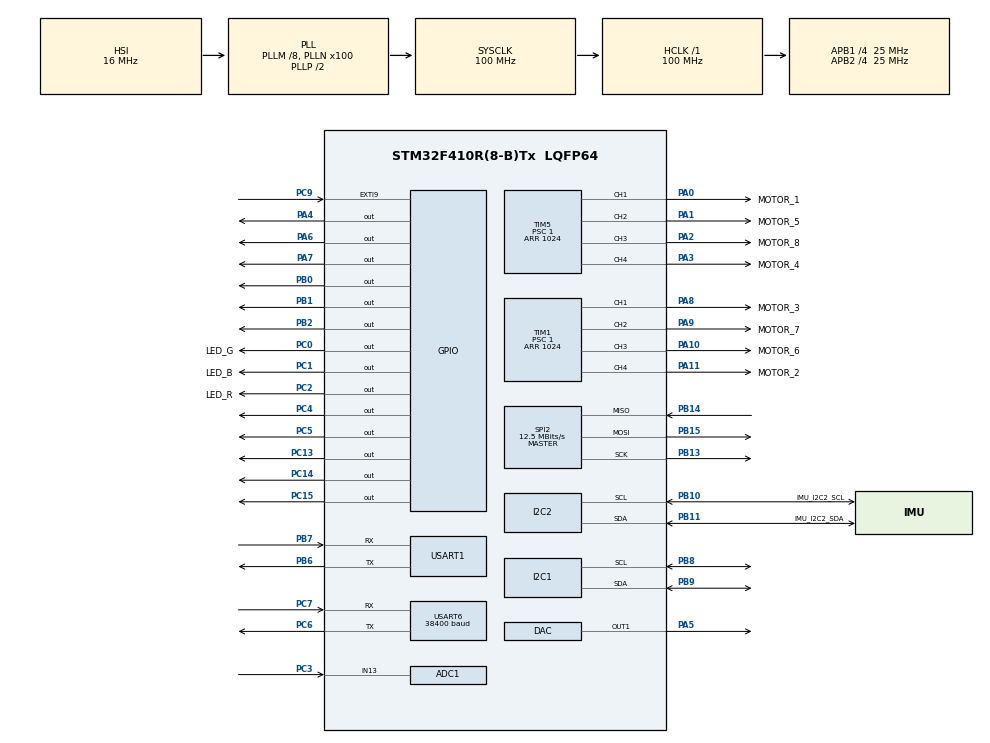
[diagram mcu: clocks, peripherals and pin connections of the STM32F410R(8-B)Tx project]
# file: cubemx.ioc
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ADC1.Channel-0\#ChannelRegularConversion=ADC_CHANNEL_13
ADC1.NbrOfConversionFlag=1
ADC1.Rank-0\#ChannelRegularConversion=1
ADC1.SamplingTime-0\#ChannelRegularConversion=ADC_SAMPLETIME_3CYCLES
ADC1.master=1
Mcu.Family=STM32F4
Mcu.Name=STM32F410R(8-B)Tx
Mcu.Package=LQFP64
NVIC.PriorityGroup=NVIC_PRIORITYGROUP_4
PA0-WKUP.GPIO_Label=MOTOR_1
PA0-WKUP.Signal=S_TIM5_CH1
PA1.GPIO_Label=MOTOR_5
PA1.Signal=S_TIM5_CH2
PA10.GPIO_Label=MOTOR_6
PA10.Signal=S_TIM1_CH3
PA11.GPIO_Label=MOTOR_2
PA11.Signal=S_TIM1_CH4
PA13.Mode=Trace_Asynchronous_SW
PA13.Signal=SYS_JTMS-SWDIO
PA14.Mode=Trace_Asynchronous_SW
PA14.Signal=SYS_JTCK-SWCLK
PA2.GPIO_Label=MOTOR_8
PA2.Signal=S_TIM5_CH3
PA3.GPIO_Label=MOTOR_4
PA3.Signal=S_TIM5_CH4
PA4.Signal=GPIO_Output
PA5.Signal=COMP_DAC1_group
PA6.Signal=GPIO_Output
PA7.Signal=GPIO_Output
PA8.GPIO_Label=MOTOR_3
PA8.Signal=S_TIM1_CH1
PA9.GPIO_Label=MOTOR_7
PA9.Signal=S_TIM1_CH2
PB0.Signal=GPIO_Output
PB1.Signal=GPIO_Output
PB10.GPIO_Label=IMU_I2C2_SCL
PB10.Mode=I2C
PB10.Signal=I2C2_SCL
PB11.GPIO_Label=IMU_I2C2_SDA
PB11.Mode=I2C
PB11.Signal=I2C2_SDA
PB13.Mode=Full_Duplex_Master
PB13.Signal=SPI2_SCK
PB14.Mode=Full_Duplex_Master
PB14.Signal=SPI2_MISO
PB15.Mode=Full_Duplex_Master
PB15.Signal=SPI2_MOSI
PB2.Signal=GPIO_Output
PB3.Mode=Trace_Asynchronous_SW
PB3.Signal=SYS_JTDO-SWO
PB6.Mode=Asynchronous
PB6.Signal=USART1_TX
PB7.Mode=Asynchronous
PB7.Signal=USART1_RX
PB8.Mode=I2C
PB8.Signal=I2C1_SCL
PB9.Mode=I2C
PB9.Signal=I2C1_SDA
PC0.GPIO_Label=LED_G
PC0.Signal=GPIO_Output
PC1.GPIO_Label=LED_B
PC1.Signal=GPIO_Output
PC13-ANTI_TAMP.Signal=GPIO_Output
PC14-OSC32_IN.Signal=GPIO_Output
PC15-OSC32_OUT.Signal=GPIO_Output
PC2.GPIO_Label=LED_R
PC2.Signal=GPIO_Output
PC3.Signal=ADCx_IN13
PC4.Signal=GPIO_Output
PC5.Signal=GPIO_Output
PC6.Mode=Asynchronous
PC6.Signal=USART6_TX
PC7.Mode=Asynchronous
PC7.Signal=USART6_RX
PC9.Signal=GPXTI9
ProjectManager.HeapSize=0x400
ProjectManager.StackSize=0x200
ProjectManager.TargetToolchain=TrueSTUDIO
RCC.48MHZClocksFreq_Value=50000000
RCC.AHBFreq_Value=100000000
RCC.APB1CLKDivider=RCC_HCLK_DIV4
RCC.APB1Freq_Value=25000000
RCC.APB1TimFreq_Value=50000000
RCC.APB2CLKDivider=RCC_HCLK_DIV4
RCC.APB2Freq_Value=25000000
RCC.APB2TimFreq_Value=50000000
RCC.CortexFreq_Value=100000000
RCC.HCLKFreq_Value=100000000
RCC.HSE_VALUE=25000000
RCC.HSI_VALUE=16000000
RCC.LSE_VALUE=32768
RCC.PLLM=8
RCC.PLLN=100
RCC.SYSCLKFreq_VALUE=100000000
RCC.SYSCLKSource=RCC_SYSCLKSOURCE_PLLCLK
RCC.VCOOutputFreq_Value=200000000
SH.ADCx_IN13.0=ADC1_IN13,IN13
SH.COMP_DAC1_group.0=DAC_OUT1,DAC_OUT1
SH.S_TIM1_CH1.0=TIM1_CH1,PWM Generation1 CH1
SH.S_TIM1_CH2.0=TIM1_CH2,PWM Generation2 CH2
SH.S_TIM1_CH3.0=TIM1_CH3,PWM Generation3 CH3
SH.S_TIM1_CH4.0=TIM1_CH4,PWM Generation4 CH4
SH.S_TIM5_CH1.0=TIM5_CH1,PWM Generation1 CH1
SH.S_TIM5_CH2.0=TIM5_CH2,PWM Generation2 CH2
SH.S_TIM5_CH3.0=TIM5_CH3,PWM Generation3 CH3
SH.S_TIM5_CH4.0=TIM5_CH4,PWM Generation4 CH4
SPI2.CalculateBaudRate=12.5 MBits/s
SPI2.Mode=SPI_MODE_MASTER
TIM1.Channel-PWM\ Generation2\ CH2=TIM_CHANNEL_2
TIM1.Channel-PWM\ Generation3\ CH3=TIM_CHANNEL_3
TIM1.Channel-PWM\ Generation4\ CH4=TIM_CHANNEL_4
TIM1.ClockDivision=TIM_CLOCKDIVISION_DIV4
TIM1.Period=1024
TIM1.Prescaler=1
TIM5.Channel-PWM\ Generation2\ CH2=TIM_CHANNEL_2
TIM5.Channel-PWM\ Generation3\ CH3=TIM_CHANNEL_3
TIM5.Channel-PWM\ Generation4\ CH4=TIM_CHANNEL_4
TIM5.Period=1024
TIM5.Prescaler=1
USART6.BaudRate=38400
VP_IWDG_VS_IWDG.Mode=IWDG_Activate
VP_TIM1_VS_ClockSourceINT.Mode=Internal
VP_TIM5_VS_ClockSourceINT.Mode=Internal
board=cubemx

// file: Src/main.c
/**
  ******************************************************************************
  * File Name          : main.c
  * Description        : Main program body
  ******************************************************************************
  *
  * COPYRIGHT(c) 2016 STMicroelectronics
  *
  * Redistribution and use in source and binary forms, with or without modification,
  * are permitted provided that the following conditions are met:
  *   1. Redistributions of source code must retain the above copyright notice,
  *      this list of conditions and the following disclaimer.
  *   2. Redistributions in binary form must reproduce the above copyright notice,
  *      this list of conditions and the following disclaimer in the documentation
  *      and/or other materials provided with the distribution.
  *   3. Neither the name of STMicroelectronics nor the names of its contributors
  *      may be used to endorse or promote products derived from this software
  *      without specific prior written permission.
  *
  * THIS SOFTWARE IS PROVIDED BY THE COPYRIGHT HOLDERS AND CONTRIBUTORS "AS IS"
  * AND ANY EXPRESS OR IMPLIED WARRANTIES, INCLUDING, BUT NOT LIMITED TO, THE
  * IMPLIED WARRANTIES OF MERCHANTABILITY AND FITNESS FOR A PARTICULAR PURPOSE ARE
  * DISCLAIMED. IN NO EVENT SHALL THE COPYRIGHT HOLDER OR CONTRIBUTORS BE LIABLE
  * FOR ANY DIRECT, INDIRECT, INCIDENTAL, SPECIAL, EXEMPLARY, OR CONSEQUENTIAL
  * DAMAGES (INCLUDING, BUT NOT LIMITED TO, PROCUREMENT OF SUBSTITUTE GOODS OR
  * SERVICES; LOSS OF USE, DATA, OR PROFITS; OR BUSINESS INTERRUPTION) HOWEVER
  * CAUSED AND ON ANY THEORY OF LIABILITY, WHETHER IN CONTRACT, STRICT LIABILITY,
  * OR TORT (INCLUDING NEGLIGENCE OR OTHERWISE) ARISING IN ANY WAY OUT OF THE USE
  * OF THIS SOFTWARE, EVEN IF ADVISED OF THE POSSIBILITY OF SUCH DAMAGE.
  *
  ******************************************************************************
  */
#include "main.h"
#include "stm32f4xx_hal.h"

ADC_HandleTypeDef hadc1;

DAC_HandleTypeDef hdac;

I2C_HandleTypeDef hi2c1;
I2C_HandleTypeDef hi2c2;

IWDG_HandleTypeDef hiwdg;

SPI_HandleTypeDef hspi2;

TIM_HandleTypeDef htim1;
TIM_HandleTypeDef htim5;

UART_HandleTypeDef huart1;
UART_HandleTypeDef huart6;

/* USER CODE BEGIN PV */
/* Private variables ---------------------------------------------------------*/

/* USER CODE END PV */

void SystemClock_Config(void);
void Error_Handler(void);
static void MX_GPIO_Init(void);
static void MX_ADC1_Init(void);
static void MX_I2C2_Init(void);
static void MX_TIM1_Init(void);
static void MX_TIM5_Init(void);
static void MX_USART6_UART_Init(void);
static void MX_IWDG_Init(void);
static void MX_I2C1_Init(void);
static void MX_USART1_UART_Init(void);
static void MX_SPI2_Init(void);
static void MX_DAC_Init(void);

void HAL_TIM_MspPostInit(TIM_HandleTypeDef *htim);

/* USER CODE BEGIN PFP */
/* Private function prototypes -----------------------------------------------*/
void dc_main();
/* USER CODE END PFP */

int main(void)
{

  /* MCU Configuration----------------------------------------------------------*/

  /* Reset of all peripherals, Initializes the Flash interface and the Systick. */
  HAL_Init();

  /* Configure the system clock */
  SystemClock_Config();

  /* Initialize all configured peripherals */
  MX_GPIO_Init();
  MX_ADC1_Init();
  MX_I2C2_Init();
  MX_TIM1_Init();
  MX_TIM5_Init();
  MX_USART6_UART_Init();
  MX_IWDG_Init();
  MX_I2C1_Init();
  MX_USART1_UART_Init();
  MX_SPI2_Init();
  MX_DAC_Init();

  /* USER CODE BEGIN 2 */
  dc_main();
  /* USER CODE END 2 */

  /* Infinite loop */
  while (1)
  {

  }

}

/** System Clock Configuration
*/
void SystemClock_Config(void)
{

  RCC_OscInitTypeDef RCC_OscInitStruct;
  RCC_ClkInitTypeDef RCC_ClkInitStruct;

    /**Configure the main internal regulator output voltage
    */
  __HAL_RCC_PWR_CLK_ENABLE();

  __HAL_PWR_VOLTAGESCALING_CONFIG(PWR_REGULATOR_VOLTAGE_SCALE1);

    /**Initializes the CPU, AHB and APB busses clocks
    */
  RCC_OscInitStruct.OscillatorType = RCC_OSCILLATORTYPE_HSI|RCC_OSCILLATORTYPE_LSI;
  RCC_OscInitStruct.HSIState = RCC_HSI_ON;
  RCC_OscInitStruct.HSICalibrationValue = 16;
  RCC_OscInitStruct.LSIState = RCC_LSI_ON;
  RCC_OscInitStruct.PLL.PLLState = RCC_PLL_ON;
  RCC_OscInitStruct.PLL.PLLSource = RCC_PLLSOURCE_HSI;
  RCC_OscInitStruct.PLL.PLLM = 8;
  RCC_OscInitStruct.PLL.PLLN = 100;
  RCC_OscInitStruct.PLL.PLLP = RCC_PLLP_DIV2;
  RCC_OscInitStruct.PLL.PLLQ = 4;
  RCC_OscInitStruct.PLL.PLLR = 2;
  if (HAL_RCC_OscConfig(&RCC_OscInitStruct) != HAL_OK)
  {
    Error_Handler();
  }

    /**Initializes the CPU, AHB and APB busses clocks
    */
  RCC_ClkInitStruct.ClockType = RCC_CLOCKTYPE_HCLK|RCC_CLOCKTYPE_SYSCLK
                              |RCC_CLOCKTYPE_PCLK1|RCC_CLOCKTYPE_PCLK2;
  RCC_ClkInitStruct.SYSCLKSource = RCC_SYSCLKSOURCE_PLLCLK;
  RCC_ClkInitStruct.AHBCLKDivider = RCC_SYSCLK_DIV1;
  RCC_ClkInitStruct.APB1CLKDivider = RCC_HCLK_DIV4;
  RCC_ClkInitStruct.APB2CLKDivider = RCC_HCLK_DIV4;

  if (HAL_RCC_ClockConfig(&RCC_ClkInitStruct, FLASH_LATENCY_3) != HAL_OK)
  {
    Error_Handler();
  }

    /**Configure the Systick interrupt time
    */
  HAL_SYSTICK_Config(HAL_RCC_GetHCLKFreq()/1000);

    /**Configure the Systick
    */
  HAL_SYSTICK_CLKSourceConfig(SYSTICK_CLKSOURCE_HCLK);

  /* SysTick_IRQn interrupt configuration */
  HAL_NVIC_SetPriority(SysTick_IRQn, 0, 0);
}

/* ADC1 init function */
static void MX_ADC1_Init(void)
{

  ADC_ChannelConfTypeDef sConfig;

    /**Configure the global features of the ADC (Clock, Resolution, Data Alignment and number of conversion)
    */
  hadc1.Instance = ADC1;
  hadc1.Init.ClockPrescaler = ADC_CLOCK_SYNC_PCLK_DIV2;
  hadc1.Init.Resolution = ADC_RESOLUTION_12B;
  hadc1.Init.ScanConvMode = DISABLE;
  hadc1.Init.ContinuousConvMode = DISABLE;
  hadc1.Init.DiscontinuousConvMode = DISABLE;
  hadc1.Init.ExternalTrigConvEdge = ADC_EXTERNALTRIGCONVEDGE_NONE;
  hadc1.Init.DataAlign = ADC_DATAALIGN_RIGHT;
  hadc1.Init.NbrOfConversion = 1;
  hadc1.Init.DMAContinuousRequests = DISABLE;
  hadc1.Init.EOCSelection = ADC_EOC_SINGLE_CONV;
  if (HAL_ADC_Init(&hadc1) != HAL_OK)
  {
    Error_Handler();
  }

    /**Configure for the selected ADC regular channel its corresponding rank in the sequencer and its sample time.
    */
  sConfig.Channel = ADC_CHANNEL_13;
  sConfig.Rank = 1;
  sConfig.SamplingTime = ADC_SAMPLETIME_3CYCLES;
  if (HAL_ADC_ConfigChannel(&hadc1, &sConfig) != HAL_OK)
  {
    Error_Handler();
  }

}

/* DAC init function */
static void MX_DAC_Init(void)
{

  DAC_ChannelConfTypeDef sConfig;

    /**DAC Initialization
    */
  hdac.Instance = DAC;
  if (HAL_DAC_Init(&hdac) != HAL_OK)
  {
    Error_Handler();
  }

    /**DAC channel OUT1 config
    */
  sConfig.DAC_Trigger = DAC_TRIGGER_NONE;
  sConfig.DAC_OutputBuffer = DAC_OUTPUTBUFFER_ENABLE;
  if (HAL_DAC_ConfigChannel(&hdac, &sConfig, DAC_CHANNEL_1) != HAL_OK)
  {
    Error_Handler();
  }

}

/* I2C1 init function */
static void MX_I2C1_Init(void)
{

  hi2c1.Instance = I2C1;
  hi2c1.Init.ClockSpeed = 100000;
  hi2c1.Init.DutyCycle = I2C_DUTYCYCLE_2;
  hi2c1.Init.OwnAddress1 = 0;
  hi2c1.Init.AddressingMode = I2C_ADDRESSINGMODE_7BIT;
  hi2c1.Init.DualAddressMode = I2C_DUALADDRESS_DISABLE;
  hi2c1.Init.OwnAddress2 = 0;
  hi2c1.Init.GeneralCallMode = I2C_GENERALCALL_DISABLE;
  hi2c1.Init.NoStretchMode = I2C_NOSTRETCH_DISABLE;
  if (HAL_I2C_Init(&hi2c1) != HAL_OK)
  {
    Error_Handler();
  }

}

/* I2C2 init function */
static void MX_I2C2_Init(void)
{

  hi2c2.Instance = I2C2;
  hi2c2.Init.ClockSpeed = 100000;
  hi2c2.Init.DutyCycle = I2C_DUTYCYCLE_2;
  hi2c2.Init.OwnAddress1 = 0;
  hi2c2.Init.AddressingMode = I2C_ADDRESSINGMODE_7BIT;
  hi2c2.Init.DualAddressMode = I2C_DUALADDRESS_DISABLE;
  hi2c2.Init.OwnAddress2 = 0;
  hi2c2.Init.GeneralCallMode = I2C_GENERALCALL_DISABLE;
  hi2c2.Init.NoStretchMode = I2C_NOSTRETCH_DISABLE;
  if (HAL_I2C_Init(&hi2c2) != HAL_OK)
  {
    Error_Handler();
  }

}

/* IWDG init function */
static void MX_IWDG_Init(void)
{

  hiwdg.Instance = IWDG;
  hiwdg.Init.Prescaler = IWDG_PRESCALER_4;
  hiwdg.Init.Reload = 4095;
  if (HAL_IWDG_Init(&hiwdg) != HAL_OK)
  {
    Error_Handler();
  }

}

/* SPI2 init function */
static void MX_SPI2_Init(void)
{

  hspi2.Instance = SPI2;
  hspi2.Init.Mode = SPI_MODE_MASTER;
  hspi2.Init.Direction = SPI_DIRECTION_2LINES;
  hspi2.Init.DataSize = SPI_DATASIZE_8BIT;
  hspi2.Init.CLKPolarity = SPI_POLARITY_LOW;
  hspi2.Init.CLKPhase = SPI_PHASE_1EDGE;
  hspi2.Init.NSS = SPI_NSS_SOFT;
  hspi2.Init.BaudRatePrescaler = SPI_BAUDRATEPRESCALER_2;
  hspi2.Init.FirstBit = SPI_FIRSTBIT_MSB;
  hspi2.Init.TIMode = SPI_TIMODE_DISABLE;
  hspi2.Init.CRCCalculation = SPI_CRCCALCULATION_DISABLE;
  hspi2.Init.CRCPolynomial = 15;
  if (HAL_SPI_Init(&hspi2) != HAL_OK)
  {
    Error_Handler();
  }

}

/* TIM1 init function */
static void MX_TIM1_Init(void)
{

  TIM_ClockConfigTypeDef sClockSourceConfig;
  TIM_MasterConfigTypeDef sMasterConfig;
  TIM_OC_InitTypeDef sConfigOC;
  TIM_BreakDeadTimeConfigTypeDef sBreakDeadTimeConfig;

  htim1.Instance = TIM1;
  htim1.Init.Prescaler = 1;
  htim1.Init.CounterMode = TIM_COUNTERMODE_UP;
  htim1.Init.Period = 1024;
  htim1.Init.ClockDivision = TIM_CLOCKDIVISION_DIV4;
  htim1.Init.RepetitionCounter = 0;
  if (HAL_TIM_Base_Init(&htim1) != HAL_OK)
  {
    Error_Handler();
  }

  sClockSourceConfig.ClockSource = TIM_CLOCKSOURCE_INTERNAL;
  if (HAL_TIM_ConfigClockSource(&htim1, &sClockSourceConfig) != HAL_OK)
  {
    Error_Handler();
  }

  if (HAL_TIM_PWM_Init(&htim1) != HAL_OK)
  {
    Error_Handler();
  }

  sMasterConfig.MasterOutputTrigger = TIM_TRGO_RESET;
  sMasterConfig.MasterSlaveMode = TIM_MASTERSLAVEMODE_DISABLE;
  if (HAL_TIMEx_MasterConfigSynchronization(&htim1, &sMasterConfig) != HAL_OK)
  {
    Error_Handler();
  }

  sConfigOC.OCMode = TIM_OCMODE_PWM1;
  sConfigOC.Pulse = 0;
  sConfigOC.OCPolarity = TIM_OCPOLARITY_HIGH;
  sConfigOC.OCNPolarity = TIM_OCNPOLARITY_HIGH;
  sConfigOC.OCFastMode = TIM_OCFAST_DISABLE;
  sConfigOC.OCIdleState = TIM_OCIDLESTATE_RESET;
  sConfigOC.OCNIdleState = TIM_OCNIDLESTATE_RESET;
  if (HAL_TIM_PWM_ConfigChannel(&htim1, &sConfigOC, TIM_CHANNEL_1) != HAL_OK)
  {
    Error_Handler();
  }

  if (HAL_TIM_PWM_ConfigChannel(&htim1, &sConfigOC, TIM_CHANNEL_2) != HAL_OK)
  {
    Error_Handler();
  }

  if (HAL_TIM_PWM_ConfigChannel(&htim1, &sConfigOC, TIM_CHANNEL_3) != HAL_OK)
  {
    Error_Handler();
  }

  if (HAL_TIM_PWM_ConfigChannel(&htim1, &sConfigOC, TIM_CHANNEL_4) != HAL_OK)
  {
    Error_Handler();
  }

  sBreakDeadTimeConfig.OffStateRunMode = TIM_OSSR_DISABLE;
  sBreakDeadTimeConfig.OffStateIDLEMode = TIM_OSSI_DISABLE;
  sBreakDeadTimeConfig.LockLevel = TIM_LOCKLEVEL_OFF;
  sBreakDeadTimeConfig.DeadTime = 0;
  sBreakDeadTimeConfig.BreakState = TIM_BREAK_DISABLE;
  sBreakDeadTimeConfig.BreakPolarity = TIM_BREAKPOLARITY_HIGH;
  sBreakDeadTimeConfig.AutomaticOutput = TIM_AUTOMATICOUTPUT_DISABLE;
  if (HAL_TIMEx_ConfigBreakDeadTime(&htim1, &sBreakDeadTimeConfig) != HAL_OK)
  {
    Error_Handler();
  }

  HAL_TIM_MspPostInit(&htim1);

}

/* TIM5 init function */
static void MX_TIM5_Init(void)
{

  TIM_ClockConfigTypeDef sClockSourceConfig;
  TIM_MasterConfigTypeDef sMasterConfig;
  TIM_OC_InitTypeDef sConfigOC;

  htim5.Instance = TIM5;
  htim5.Init.Prescaler = 1;
  htim5.Init.CounterMode = TIM_COUNTERMODE_UP;
  htim5.Init.Period = 1024;
  htim5.Init.ClockDivision = TIM_CLOCKDIVISION_DIV1;
  if (HAL_TIM_Base_Init(&htim5) != HAL_OK)
  {
    Error_Handler();
  }

  sClockSourceConfig.ClockSource = TIM_CLOCKSOURCE_INTERNAL;
  if (HAL_TIM_ConfigClockSource(&htim5, &sClockSourceConfig) != HAL_OK)
  {
    Error_Handler();
  }

  if (HAL_TIM_PWM_Init(&htim5) != HAL_OK)
  {
    Error_Handler();
  }

  sMasterConfig.MasterOutputTrigger = TIM_TRGO_RESET;
  sMasterConfig.MasterSlaveMode = TIM_MASTERSLAVEMODE_DISABLE;
  if (HAL_TIMEx_MasterConfigSynchronization(&htim5, &sMasterConfig) != HAL_OK)
  {
    Error_Handler();
  }

  sConfigOC.OCMode = TIM_OCMODE_PWM1;
  sConfigOC.Pulse = 0;
  sConfigOC.OCPolarity = TIM_OCPOLARITY_HIGH;
  sConfigOC.OCFastMode = TIM_OCFAST_DISABLE;
  if (HAL_TIM_PWM_ConfigChannel(&htim5, &sConfigOC, TIM_CHANNEL_1) != HAL_OK)
  {
    Error_Handler();
  }

  if (HAL_TIM_PWM_ConfigChannel(&htim5, &sConfigOC, TIM_CHANNEL_2) != HAL_OK)
  {
    Error_Handler();
  }

  if (HAL_TIM_PWM_ConfigChannel(&htim5, &sConfigOC, TIM_CHANNEL_3) != HAL_OK)
  {
    Error_Handler();
  }

  if (HAL_TIM_PWM_ConfigChannel(&htim5, &sConfigOC, TIM_CHANNEL_4) != HAL_OK)
  {
    Error_Handler();
  }

  HAL_TIM_MspPostInit(&htim5);

}

/* USART1 init function */
static void MX_USART1_UART_Init(void)
{

  huart1.Instance = USART1;
  huart1.Init.BaudRate = 115200;
  huart1.Init.WordLength = UART_WORDLENGTH_8B;
  huart1.Init.StopBits = UART_STOPBITS_1;
  huart1.Init.Parity = UART_PARITY_NONE;
  huart1.Init.Mode = UART_MODE_TX_RX;
  huart1.Init.HwFlowCtl = UART_HWCONTROL_NONE;
  huart1.Init.OverSampling = UART_OVERSAMPLING_16;
  if (HAL_UART_Init(&huart1) != HAL_OK)
  {
    Error_Handler();
  }

}

/* USART6 init function */
static void MX_USART6_UART_Init(void)
{

  huart6.Instance = USART6;
  huart6.Init.BaudRate = 38400;
  huart6.Init.WordLength = UART_WORDLENGTH_8B;
  huart6.Init.StopBits = UART_STOPBITS_1;
  huart6.Init.Parity = UART_PARITY_NONE;
  huart6.Init.Mode = UART_MODE_TX_RX;
  huart6.Init.HwFlowCtl = UART_HWCONTROL_NONE;
  huart6.Init.OverSampling = UART_OVERSAMPLING_16;
  if (HAL_UART_Init(&huart6) != HAL_OK)
  {
    Error_Handler();
  }

}

/** Configure pins as
        * Analog
        * Input
        * Output
        * EVENT_OUT
        * EXTI
*/
static void MX_GPIO_Init(void)
{

  GPIO_InitTypeDef GPIO_InitStruct;

  /* GPIO Ports Clock Enable */
  __HAL_RCC_GPIOC_CLK_ENABLE();
  __HAL_RCC_GPIOA_CLK_ENABLE();
  __HAL_RCC_GPIOB_CLK_ENABLE();

  /*Configure GPIO pin Output Level */
  HAL_GPIO_WritePin(GPIOC, GPIO_PIN_13|GPIO_PIN_14|GPIO_PIN_15|LED_G_Pin
                          |LED_B_Pin|LED_R_Pin|GPIO_PIN_4|GPIO_PIN_5, GPIO_PIN_RESET);

  /*Configure GPIO pin Output Level */
  HAL_GPIO_WritePin(GPIOA, GPIO_PIN_4|GPIO_PIN_6|GPIO_PIN_7, GPIO_PIN_RESET);

  /*Configure GPIO pin Output Level */
  HAL_GPIO_WritePin(GPIOB, GPIO_PIN_0|GPIO_PIN_1|GPIO_PIN_2, GPIO_PIN_RESET);

  /*Configure GPIO pins : PC13 PC14 PC15 LED_G_Pin
                           LED_B_Pin LED_R_Pin PC4 PC5 */
  GPIO_InitStruct.Pin = GPIO_PIN_13|GPIO_PIN_14|GPIO_PIN_15|LED_G_Pin
                          |LED_B_Pin|LED_R_Pin|GPIO_PIN_4|GPIO_PIN_5;
  GPIO_InitStruct.Mode = GPIO_MODE_OUTPUT_PP;
  GPIO_InitStruct.Pull = GPIO_NOPULL;
  GPIO_InitStruct.Speed = GPIO_SPEED_FREQ_LOW;
  HAL_GPIO_Init(GPIOC, &GPIO_InitStruct);

  /*Configure GPIO pins : PA4 PA6 PA7 */
  GPIO_InitStruct.Pin = GPIO_PIN_4|GPIO_PIN_6|GPIO_PIN_7;
  GPIO_InitStruct.Mode = GPIO_MODE_OUTPUT_PP;
  GPIO_InitStruct.Pull = GPIO_NOPULL;
  GPIO_InitStruct.Speed = GPIO_SPEED_FREQ_LOW;
  HAL_GPIO_Init(GPIOA, &GPIO_InitStruct);

  /*Configure GPIO pins : PB0 PB1 PB2 */
  GPIO_InitStruct.Pin = GPIO_PIN_0|GPIO_PIN_1|GPIO_PIN_2;
  GPIO_InitStruct.Mode = GPIO_MODE_OUTPUT_PP;
  GPIO_InitStruct.Pull = GPIO_NOPULL;
  GPIO_InitStruct.Speed = GPIO_SPEED_FREQ_LOW;
  HAL_GPIO_Init(GPIOB, &GPIO_InitStruct);

  /*Configure GPIO pin : PC9 */
  GPIO_InitStruct.Pin = GPIO_PIN_9;
  GPIO_InitStruct.Mode = GPIO_MODE_IT_RISING;
  GPIO_InitStruct.Pull = GPIO_NOPULL;
  HAL_GPIO_Init(GPIOC, &GPIO_InitStruct);

}

void Error_Handler(void)
{
  while(1)
  {
  }
}

/************************ (C) COPYRIGHT STMicroelectronics *****END OF FILE****/
